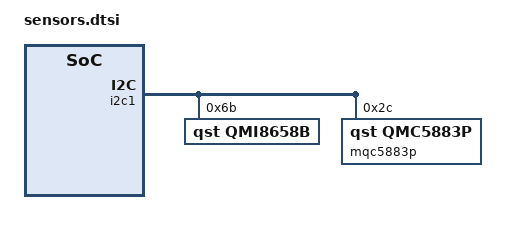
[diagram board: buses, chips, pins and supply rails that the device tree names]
/*
 * Whisplay Hat+ sensor overlay fragments.
 *
 * The demo accesses QMI8658B/MQC5883P from user space, but the nodes document
 * the fixed I2C1 addresses and allow future kernel drivers to bind.
 */

fragment@10 {
	target = <&i2c1>;
	__overlay__ {
		#address-cells = <1>;
		#size-cells = <0>;
		status = "okay";

		qmi8658b@6b {
			compatible = "qst,qmi8658b";
			reg = <0x6b>;
			status = "okay";
		};

		mqc5883p@2c {
			compatible = "qst,qmc5883p";
			reg = <0x2c>;
			status = "okay";
		};
	};
};
